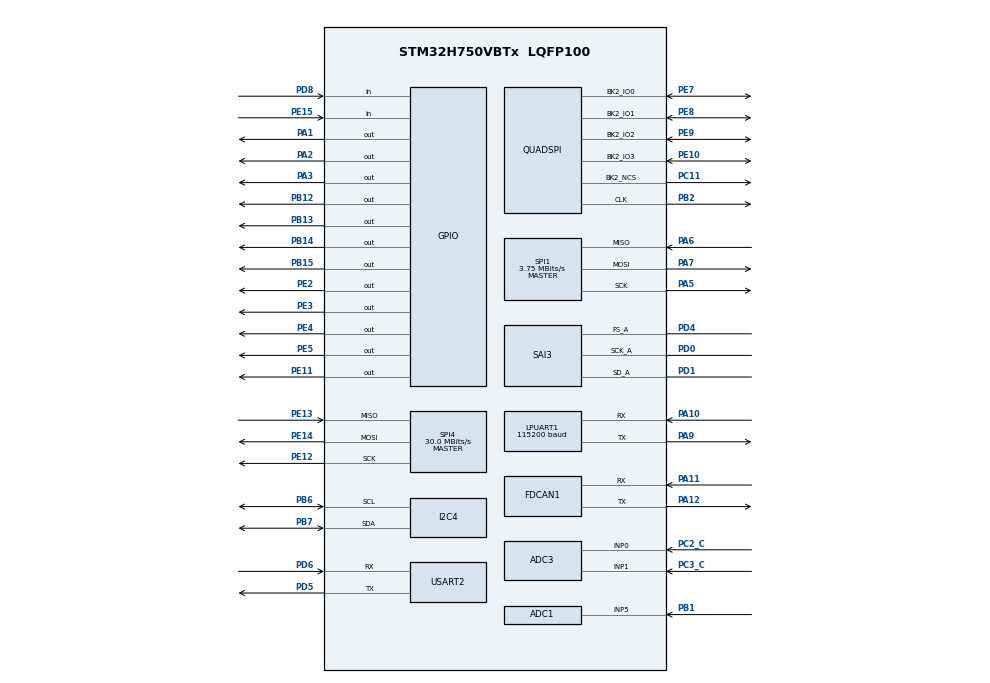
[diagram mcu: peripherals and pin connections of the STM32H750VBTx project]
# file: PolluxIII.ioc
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ADC1.Channel-0\#ChannelRegularConversion=ADC_CHANNEL_5
ADC1.ClockPrescaler=ADC_CLOCK_ASYNC_DIV2
ADC1.NbrOfConversionFlag=1
ADC1.OffsetNumber-0\#ChannelRegularConversion=ADC_OFFSET_NONE
ADC1.OffsetSignedSaturation-0\#ChannelRegularConversion=DISABLE
ADC1.Rank-0\#ChannelRegularConversion=1
ADC1.SamplingTime-0\#ChannelRegularConversion=ADC_SAMPLETIME_1CYCLE_5
ADC1.master=1
ADC2.Channel-0\#ChannelRegularConversion=ADC_CHANNEL_5
ADC2.ClockPrescaler=ADC_CLOCK_ASYNC_DIV2
ADC2.NbrOfConversionFlag=1
ADC2.OffsetNumber-0\#ChannelRegularConversion=ADC_OFFSET_NONE
ADC2.OffsetSignedSaturation-0\#ChannelRegularConversion=DISABLE
ADC2.Rank-0\#ChannelRegularConversion=1
ADC2.SamplingTime-0\#ChannelRegularConversion=ADC_SAMPLETIME_1CYCLE_5
ADC3.Channel-0\#ChannelRegularConversion=ADC_CHANNEL_0
ADC3.ClockPrescaler=ADC_CLOCK_ASYNC_DIV2
ADC3.NbrOfConversionFlag=1
ADC3.OffsetNumber-0\#ChannelRegularConversion=ADC_OFFSET_NONE
ADC3.OffsetSignedSaturation-0\#ChannelRegularConversion=DISABLE
ADC3.Rank-0\#ChannelRegularConversion=1
ADC3.SamplingTime-0\#ChannelRegularConversion=ADC_SAMPLETIME_1CYCLE_5
Bdma.LPUART1_RX.0.Direction=DMA_PERIPH_TO_MEMORY
Bdma.LPUART1_RX.0.EventEnable=DISABLE
Bdma.LPUART1_RX.0.Instance=BDMA_Channel0
Bdma.LPUART1_RX.0.MemDataAlignment=DMA_MDATAALIGN_BYTE
Bdma.LPUART1_RX.0.MemInc=DMA_MINC_ENABLE
Bdma.LPUART1_RX.0.Mode=DMA_NORMAL
Bdma.LPUART1_RX.0.PeriphDataAlignment=DMA_PDATAALIGN_BYTE
Bdma.LPUART1_RX.0.PeriphInc=DMA_PINC_DISABLE
Bdma.LPUART1_RX.0.Polarity=HAL_DMAMUX_REQ_GEN_RISING
Bdma.LPUART1_RX.0.Priority=DMA_PRIORITY_LOW
Bdma.LPUART1_RX.0.RequestNumber=1
Bdma.LPUART1_RX.0.SignalID=NONE
Bdma.LPUART1_RX.0.SyncEnable=DISABLE
Bdma.LPUART1_RX.0.SyncPolarity=HAL_DMAMUX_SYNC_NO_EVENT
Bdma.LPUART1_RX.0.SyncRequestNumber=1
Bdma.LPUART1_RX.0.SyncSignalID=NONE
Bdma.LPUART1_TX.1.Direction=DMA_MEMORY_TO_PERIPH
Bdma.LPUART1_TX.1.EventEnable=DISABLE
Bdma.LPUART1_TX.1.Instance=BDMA_Channel1
Bdma.LPUART1_TX.1.MemDataAlignment=DMA_MDATAALIGN_BYTE
Bdma.LPUART1_TX.1.MemInc=DMA_MINC_ENABLE
Bdma.LPUART1_TX.1.Mode=DMA_NORMAL
Bdma.LPUART1_TX.1.PeriphDataAlignment=DMA_PDATAALIGN_BYTE
Bdma.LPUART1_TX.1.PeriphInc=DMA_PINC_DISABLE
Bdma.LPUART1_TX.1.Polarity=HAL_DMAMUX_REQ_GEN_RISING
Bdma.LPUART1_TX.1.Priority=DMA_PRIORITY_LOW
Bdma.LPUART1_TX.1.RequestNumber=1
Bdma.LPUART1_TX.1.SignalID=NONE
Bdma.LPUART1_TX.1.SyncEnable=DISABLE
Bdma.LPUART1_TX.1.SyncPolarity=HAL_DMAMUX_SYNC_NO_EVENT
Bdma.LPUART1_TX.1.SyncRequestNumber=1
Bdma.LPUART1_TX.1.SyncSignalID=NONE
Bdma.Request0=LPUART1_RX
Bdma.Request1=LPUART1_TX
Bdma.RequestsNb=2
Dma.Request0=USART2_RX
Dma.Request1=SPI4_RX
Dma.Request2=SPI4_TX
Dma.SPI4_RX.1.Direction=DMA_PERIPH_TO_MEMORY
Dma.SPI4_RX.1.EventEnable=DISABLE
Dma.SPI4_RX.1.FIFOMode=DMA_FIFOMODE_ENABLE
Dma.SPI4_RX.1.FIFOThreshold=DMA_FIFO_THRESHOLD_3QUARTERSFULL
Dma.SPI4_RX.1.Instance=DMA1_Stream1
Dma.SPI4_RX.1.MemBurst=DMA_MBURST_SINGLE
Dma.SPI4_RX.1.MemDataAlignment=DMA_MDATAALIGN_BYTE
Dma.SPI4_RX.1.MemInc=DMA_MINC_ENABLE
Dma.SPI4_RX.1.Mode=DMA_NORMAL
Dma.SPI4_RX.1.PeriphBurst=DMA_PBURST_SINGLE
Dma.SPI4_RX.1.PeriphDataAlignment=DMA_PDATAALIGN_BYTE
Dma.SPI4_RX.1.PeriphInc=DMA_PINC_DISABLE
Dma.SPI4_RX.1.Polarity=HAL_DMAMUX_REQ_GEN_RISING
Dma.SPI4_RX.1.Priority=DMA_PRIORITY_LOW
Dma.SPI4_RX.1.RequestNumber=1
Dma.SPI4_RX.1.SignalID=NONE
Dma.SPI4_RX.1.SyncEnable=DISABLE
Dma.SPI4_RX.1.SyncPolarity=HAL_DMAMUX_SYNC_NO_EVENT
Dma.SPI4_RX.1.SyncRequestNumber=1
Dma.SPI4_RX.1.SyncSignalID=NONE
Dma.SPI4_TX.2.Direction=DMA_MEMORY_TO_PERIPH
Dma.SPI4_TX.2.EventEnable=DISABLE
Dma.SPI4_TX.2.FIFOMode=DMA_FIFOMODE_ENABLE
Dma.SPI4_TX.2.FIFOThreshold=DMA_FIFO_THRESHOLD_3QUARTERSFULL
Dma.SPI4_TX.2.Instance=DMA1_Stream2
Dma.SPI4_TX.2.MemBurst=DMA_MBURST_SINGLE
Dma.SPI4_TX.2.MemDataAlignment=DMA_MDATAALIGN_BYTE
Dma.SPI4_TX.2.MemInc=DMA_MINC_ENABLE
Dma.SPI4_TX.2.Mode=DMA_NORMAL
Dma.SPI4_TX.2.PeriphBurst=DMA_PBURST_SINGLE
Dma.SPI4_TX.2.PeriphDataAlignment=DMA_PDATAALIGN_BYTE
Dma.SPI4_TX.2.PeriphInc=DMA_PINC_DISABLE
Dma.SPI4_TX.2.Polarity=HAL_DMAMUX_REQ_GEN_RISING
Dma.SPI4_TX.2.Priority=DMA_PRIORITY_LOW
Dma.SPI4_TX.2.RequestNumber=1
Dma.SPI4_TX.2.SignalID=NONE
Dma.SPI4_TX.2.SyncEnable=DISABLE
Dma.SPI4_TX.2.SyncPolarity=HAL_DMAMUX_SYNC_NO_EVENT
Dma.SPI4_TX.2.SyncRequestNumber=1
Dma.SPI4_TX.2.SyncSignalID=NONE
Dma.USART2_RX.0.Direction=DMA_PERIPH_TO_MEMORY
Dma.USART2_RX.0.EventEnable=DISABLE
Dma.USART2_RX.0.FIFOMode=DMA_FIFOMODE_ENABLE
Dma.USART2_RX.0.FIFOThreshold=DMA_FIFO_THRESHOLD_FULL
Dma.USART2_RX.0.Instance=DMA1_Stream0
Dma.USART2_RX.0.MemBurst=DMA_MBURST_SINGLE
Dma.USART2_RX.0.MemDataAlignment=DMA_MDATAALIGN_BYTE
Dma.USART2_RX.0.MemInc=DMA_MINC_ENABLE
Dma.USART2_RX.0.Mode=DMA_CIRCULAR
Dma.USART2_RX.0.PeriphBurst=DMA_PBURST_SINGLE
Dma.USART2_RX.0.PeriphDataAlignment=DMA_PDATAALIGN_BYTE
Dma.USART2_RX.0.PeriphInc=DMA_PINC_DISABLE
Dma.USART2_RX.0.Polarity=HAL_DMAMUX_REQ_GEN_RISING
Dma.USART2_RX.0.Priority=DMA_PRIORITY_VERY_HIGH
Dma.USART2_RX.0.RequestNumber=1
Dma.USART2_RX.0.SignalID=NONE
Dma.USART2_RX.0.SyncEnable=DISABLE
Dma.USART2_RX.0.SyncPolarity=HAL_DMAMUX_SYNC_NO_EVENT
Dma.USART2_RX.0.SyncRequestNumber=1
Dma.USART2_RX.0.SyncSignalID=NONE
FREERTOS.Tasks01=systemd,0,1024,systemd_main,Default,NULL,Dynamic,NULL,NULL
FREERTOS.configCHECK_FOR_STACK_OVERFLOW=1
FREERTOS.configTOTAL_HEAP_SIZE=262144
FREERTOS.configUSE_COUNTING_SEMAPHORES=1
FREERTOS.configUSE_NEWLIB_REENTRANT=1
I2C4.Speed=100
I2C4.Timing=0x307075B1
JPEG.JPEG_RGB_FORMAT=JPEG_RGB565
LPUART1.BaudRate=115200
LPUART1.FIFOMode=UART_FIFOMODE_ENABLE
LPUART1.OverrunDisableParam=UART_ADVFEATURE_OVERRUN_DISABLE
LPUART1.RXFIFOThreshold=UART_RXFIFO_THRESHOLD_1_2
LPUART1.TXFIFOThreshold=UART_TXFIFO_THRESHOLD_1_2
Mcu.Family=STM32H7
Mcu.Name=STM32H750VBTx
Mcu.Package=LQFP100
Mdma.MDMA_Channel0.JPEG_INFIFO_TH.0.BlockCount=0
Mdma.MDMA_Channel0.JPEG_INFIFO_TH.0.BlockDataLength=0
Mdma.MDMA_Channel0.JPEG_INFIFO_TH.0.BufferTransferLength=32
Mdma.MDMA_Channel0.JPEG_INFIFO_TH.0.CircularMode=MDMA_LINEAR_LIST
Mdma.MDMA_Channel0.JPEG_INFIFO_TH.0.DataAlignment=MDMA_DATAALIGN_PACKENABLE
Mdma.MDMA_Channel0.JPEG_INFIFO_TH.0.DestBlockAddressOffset=0
Mdma.MDMA_Channel0.JPEG_INFIFO_TH.0.DestBurst=MDMA_DEST_BURST_SINGLE
Mdma.MDMA_Channel0.JPEG_INFIFO_TH.0.DestDataSize=MDMA_DEST_DATASIZE_WORD
Mdma.MDMA_Channel0.JPEG_INFIFO_TH.0.DestinationInc=MDMA_DEST_INC_DISABLE
Mdma.MDMA_Channel0.JPEG_INFIFO_TH.0.DstAddress=0
Mdma.MDMA_Channel0.JPEG_INFIFO_TH.0.Endianness=MDMA_LITTLE_ENDIANNESS_PRESERVE
Mdma.MDMA_Channel0.JPEG_INFIFO_TH.0.Instance=MDMA_Channel0
Mdma.MDMA_Channel0.JPEG_INFIFO_TH.0.MaskAddress=0
Mdma.MDMA_Channel0.JPEG_INFIFO_TH.0.MaskData=0
Mdma.MDMA_Channel0.JPEG_INFIFO_TH.0.Priority=MDMA_PRIORITY_LOW
Mdma.MDMA_Channel0.JPEG_INFIFO_TH.0.Rank=First
Mdma.MDMA_Channel0.JPEG_INFIFO_TH.0.SourceBlockAddressOffset=0
Mdma.MDMA_Channel0.JPEG_INFIFO_TH.0.SourceBurst=MDMA_SOURCE_BURST_SINGLE
Mdma.MDMA_Channel0.JPEG_INFIFO_TH.0.SourceDataSize=MDMA_SRC_DATASIZE_BYTE
Mdma.MDMA_Channel0.JPEG_INFIFO_TH.0.SourceInc=MDMA_SRC_INC_BYTE
Mdma.MDMA_Channel0.JPEG_INFIFO_TH.0.SrcAddress=0
Mdma.MDMA_Channel0.JPEG_INFIFO_TH.0.TransferTriggerMode=MDMA_BUFFER_TRANSFER
Mdma.MDMA_Channel0.Request0=JPEG_INFIFO_TH
Mdma.MDMA_Channel0.RequestsNb=1
Mdma.MDMA_Channel1.JPEG_OUTFIFO_TH.0.BlockCount=0
Mdma.MDMA_Channel1.JPEG_OUTFIFO_TH.0.BlockDataLength=0
Mdma.MDMA_Channel1.JPEG_OUTFIFO_TH.0.BufferTransferLength=32
Mdma.MDMA_Channel1.JPEG_OUTFIFO_TH.0.CircularMode=MDMA_LINEAR_LIST
Mdma.MDMA_Channel1.JPEG_OUTFIFO_TH.0.DataAlignment=MDMA_DATAALIGN_PACKENABLE
Mdma.MDMA_Channel1.JPEG_OUTFIFO_TH.0.DestBlockAddressOffset=0
Mdma.MDMA_Channel1.JPEG_OUTFIFO_TH.0.DestBurst=MDMA_DEST_BURST_SINGLE
Mdma.MDMA_Channel1.JPEG_OUTFIFO_TH.0.DestDataSize=MDMA_DEST_DATASIZE_BYTE
Mdma.MDMA_Channel1.JPEG_OUTFIFO_TH.0.DestinationInc=MDMA_DEST_INC_BYTE
Mdma.MDMA_Channel1.JPEG_OUTFIFO_TH.0.DstAddress=0
Mdma.MDMA_Channel1.JPEG_OUTFIFO_TH.0.Endianness=MDMA_LITTLE_ENDIANNESS_PRESERVE
Mdma.MDMA_Channel1.JPEG_OUTFIFO_TH.0.Instance=MDMA_Channel1
Mdma.MDMA_Channel1.JPEG_OUTFIFO_TH.0.MaskAddress=0
Mdma.MDMA_Channel1.JPEG_OUTFIFO_TH.0.MaskData=0
Mdma.MDMA_Channel1.JPEG_OUTFIFO_TH.0.Priority=MDMA_PRIORITY_LOW
Mdma.MDMA_Channel1.JPEG_OUTFIFO_TH.0.Rank=First
Mdma.MDMA_Channel1.JPEG_OUTFIFO_TH.0.SourceBlockAddressOffset=0
Mdma.MDMA_Channel1.JPEG_OUTFIFO_TH.0.SourceBurst=MDMA_SOURCE_BURST_SINGLE
Mdma.MDMA_Channel1.JPEG_OUTFIFO_TH.0.SourceDataSize=MDMA_SRC_DATASIZE_WORD
Mdma.MDMA_Channel1.JPEG_OUTFIFO_TH.0.SourceInc=MDMA_SRC_INC_DISABLE
Mdma.MDMA_Channel1.JPEG_OUTFIFO_TH.0.SrcAddress=0
Mdma.MDMA_Channel1.JPEG_OUTFIFO_TH.0.TransferTriggerMode=MDMA_BUFFER_TRANSFER
Mdma.MDMA_Channel1.Request0=JPEG_OUTFIFO_TH
Mdma.MDMA_Channel1.RequestsNb=1
Mdma.RequestSet0=MDMA_Channel0
Mdma.RequestSet1=MDMA_Channel1
Mdma.RequestSetsNb=2
NVIC.BDMA_Channel0_IRQn=true\:5\:0\:false\:false\:true\:true\:false\:true
NVIC.BDMA_Channel1_IRQn=true\:5\:0\:false\:false\:true\:true\:false\:true
NVIC.DMA1_Stream0_IRQn=true\:5\:0\:false\:false\:true\:true\:false\:true
NVIC.DMA1_Stream1_IRQn=true\:5\:0\:false\:false\:true\:false\:true\:true
NVIC.DMA1_Stream2_IRQn=true\:5\:0\:false\:false\:true\:false\:true\:true
NVIC.MDMA_IRQn=true\:5\:0\:false\:false\:true\:true\:false\:true
NVIC.PriorityGroup=NVIC_PRIORITYGROUP_4
NVIC.SPI4_IRQn=true\:5\:0\:false\:false\:true\:false\:true\:true
NVIC.TIM1_UP_IRQn=true\:15\:0\:false\:false\:true\:false\:false\:true
NVIC.TimeBase=TIM1_UP_IRQn
NVIC.TimeBaseIP=TIM1
NVIC.USART2_IRQn=true\:5\:0\:false\:false\:true\:true\:true\:true
PA1.Signal=GPIO_Output
PA10.Mode=Asynchronous
PA10.Signal=LPUART1_RX
PA11.Mode=FDCAN_Activate
PA11.Signal=FDCAN1_RX
PA12.Mode=FDCAN_Activate
PA12.Signal=FDCAN1_TX
PA13\ (JTMS/SWDIO).Mode=JTAG_5_pins
PA13\ (JTMS/SWDIO).Signal=DEBUG_JTMS-SWDIO
PA14\ (JTCK/SWCLK).Mode=JTAG_5_pins
PA14\ (JTCK/SWCLK).Signal=DEBUG_JTCK-SWCLK
PA15\ (JTDI).Mode=JTAG_5_pins
PA15\ (JTDI).Signal=DEBUG_JTDI
PA2.Signal=GPIO_Output
PA3.Signal=GPIO_Output
PA5.Mode=Full_Duplex_Master
PA5.Signal=SPI1_SCK
PA6.Mode=Full_Duplex_Master
PA6.Signal=SPI1_MISO
PA7.Mode=Full_Duplex_Master
PA7.Signal=SPI1_MOSI
PA9.Mode=Asynchronous
PA9.Signal=LPUART1_TX
PB1.Signal=ADCx_INP5
PB12.PinState=GPIO_PIN_SET
PB12.Signal=GPIO_Output
PB13.PinState=GPIO_PIN_SET
PB13.Signal=GPIO_Output
PB14.Signal=GPIO_Output
PB15.Signal=GPIO_Output
PB2.GPIO_Speed=GPIO_SPEED_FREQ_VERY_HIGH
PB2.Mode=Single Bank 2
PB2.Signal=QUADSPI_CLK
PB3\ (JTDO/TRACESWO).Mode=JTAG_5_pins
PB3\ (JTDO/TRACESWO).Signal=DEBUG_JTDO-SWO
PB4\ (NJTRST).Mode=JTAG_5_pins
PB4\ (NJTRST).Signal=DEBUG_JTRST
PB6.GPIO_Pu=GPIO_PULLUP
PB6.Mode=I2C
PB6.Signal=I2C4_SCL
PB7.GPIO_Pu=GPIO_PULLUP
PB7.Mode=I2C
PB7.Signal=I2C4_SDA
PC11.GPIO_Speed=GPIO_SPEED_FREQ_VERY_HIGH
PC11.Mode=Single Bank 2
PC11.Signal=QUADSPI_BK2_NCS
PC2_C.Mode=IN0-Single-Ended
PC2_C.Signal=ADC3_INP0
PC3_C.Mode=IN1-Single-Ended
PC3_C.Signal=ADC3_INP1
PD0.Mode=SAI_A_Master
PD0.Signal=SAI3_SCK_A
PD1.Mode=SAI_A_Master
PD1.Signal=SAI3_SD_A
PD4.Mode=SAI_A_Master
PD4.Signal=SAI3_FS_A
PD5.Mode=Asynchronous
PD5.Signal=USART2_TX
PD6.Mode=Asynchronous
PD6.Signal=USART2_RX
PD8.Signal=GPIO_Input
PE10.GPIO_Speed=GPIO_SPEED_FREQ_VERY_HIGH
PE10.Mode=Single Bank 2
PE10.Signal=QUADSPI_BK2_IO3
PE11.Signal=GPIO_Output
PE12.Mode=Full_Duplex_Master
PE12.Signal=SPI4_SCK
PE13.Mode=Full_Duplex_Master
PE13.Signal=SPI4_MISO
PE14.Mode=Full_Duplex_Master
PE14.Signal=SPI4_MOSI
PE15.Signal=GPIO_Input
PE2.PinState=GPIO_PIN_SET
PE2.Signal=GPIO_Output
PE3.PinState=GPIO_PIN_SET
PE3.Signal=GPIO_Output
PE4.Signal=GPIO_Output
PE5.Signal=GPIO_Output
PE7.GPIO_Speed=GPIO_SPEED_FREQ_VERY_HIGH
PE7.Mode=Single Bank 2
PE7.Signal=QUADSPI_BK2_IO0
PE8.GPIO_Speed=GPIO_SPEED_FREQ_VERY_HIGH
PE8.Mode=Single Bank 2
PE8.Signal=QUADSPI_BK2_IO1
PE9.GPIO_Speed=GPIO_SPEED_FREQ_VERY_HIGH
PE9.Mode=Single Bank 2
PE9.Signal=QUADSPI_BK2_IO2
PH0-OSC_IN\ (PH0).Mode=HSE-External-Oscillator
PH0-OSC_IN\ (PH0).Signal=RCC_OSC_IN
PH1-OSC_OUT\ (PH1).Mode=HSE-External-Oscillator
PH1-OSC_OUT\ (PH1).Signal=RCC_OSC_OUT
ProjectManager.HeapSize=0x200
ProjectManager.StackSize=0x400
ProjectManager.TargetToolchain=STM32CubeIDE
QUADSPI.ClockMode=QSPI_CLOCK_MODE_3
QUADSPI.FlashSize=29
QUADSPI.SampleShifting=QSPI_SAMPLE_SHIFTING_HALFCYCLE
RCC.ADCCLockSelection=RCC_ADCCLKSOURCE_PLL3
RCC.ADCFreq_Value=150000000
RCC.APB1Freq_Value=120000000
RCC.APB2Freq_Value=120000000
RCC.APB3Freq_Value=120000000
RCC.APB4Freq_Value=120000000
RCC.CortexFreq_Value=480000000
RCC.D1PPRE=RCC_APB3_DIV2
RCC.D2PPRE1=RCC_APB1_DIV2
RCC.D2PPRE2=RCC_APB2_DIV2
RCC.D3PPRE=RCC_APB4_DIV2
RCC.DIVM1=2
RCC.DIVM2=2
RCC.DIVM3=16
RCC.DIVN1=64
RCC.DIVN2=16
RCC.DIVN3=160
RCC.FDCANCLockSelection=RCC_FDCANCLKSOURCE_PLL2
RCC.HCLKFreq_Value=240000000
RCC.HPRE=RCC_HCLK_DIV2
RCC.HSE_VALUE=30000000
RCC.HSIDiv=RCC_PLLSAIDIVR_8
RCC.PLL1_VCI_Range-AdvancedSettings=RCC_PLL1VCIRANGE_0
RCC.PLL1_VCO_SEL-AdvancedSettings=RCC_PLL1VCOMEDIUM
RCC.PLL2FRACN=0
RCC.PLL2_VCI_Range-AdvancedSettings=RCC_PLL2VCIRANGE_0
RCC.PLL3FRACN=0
RCC.PLLFRACN=0
RCC.PLLSourceVirtual=RCC_PLLSOURCE_HSE
RCC.SAI23CLockSelection=RCC_SAI23CLKSOURCE_PLL3
RCC.SPI123CLockSelection=RCC_SPI123CLKSOURCE_PLL2
RCC.SYSCLKFreq_VALUE=480000000
RCC.SYSCLKSource=RCC_SYSCLKSOURCE_PLLCLK
RCC.USBFreq_Value=480000000
SAI3.ErrorAudioFreq-SAI_A_Master=52.58 %
SAI3.Instance-SAI_A_Master=SAI$Index_Block_A
SAI3.MClockEnable-SAI_A_Master=SAI_MASTERCLOCK_DISABLE
SAI3.RealAudioFreq-SAI_A_Master=292.968 KHz
SAI3.VirtualMode-SAI_A_Master=VM_MASTER
SH.ADCx_INP5.0=ADC1_INP5,IN5-Single-Ended
SH.ADCx_INP5.1=ADC2_INP5,IN5-Single-Ended
SPI1.BaudRatePrescaler=SPI_BAUDRATEPRESCALER_32
SPI1.CLKPolarity=SPI_POLARITY_HIGH
SPI1.CalculateBaudRate=3.75 MBits/s
SPI1.DataSize=SPI_DATASIZE_8BIT
SPI1.Direction=SPI_DIRECTION_2LINES
SPI1.Mode=SPI_MODE_MASTER
SPI1.VirtualType=VM_MASTER
SPI4.BaudRatePrescaler=SPI_BAUDRATEPRESCALER_4
SPI4.CalculateBaudRate=30.0 MBits/s
SPI4.DataSize=SPI_DATASIZE_8BIT
SPI4.Direction=SPI_DIRECTION_2LINES
SPI4.Mode=SPI_MODE_MASTER
SPI4.VirtualType=VM_MASTER
TIM2.AutoReloadPreload=TIM_AUTORELOAD_PRELOAD_ENABLE
TIM2.Prescaler=240
USART2.VirtualMode-Asynchronous=VM_ASYNC
VP_FREERTOS_VS_CMSIS_V1.Mode=CMSIS_V1
VP_IWDG1_VS_IWDG.Mode=IWDG_Activate
VP_JPEG_VS_JPEG.Mode=JPEG_Activate
VP_SYS_VS_tim1.Mode=TIM1
VP_TIM2_VS_ClockSourceITR.Mode=TriggerSource_ITR0
board=custom

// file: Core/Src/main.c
/* USER CODE BEGIN Header */
/**
  ******************************************************************************
  * @file           : main.c
  * @brief          : Main program body
  ******************************************************************************
  * @attention
  *
  * <h2><center>&copy; Copyright (c) 2021 STMicroelectronics.
  * All rights reserved.</center></h2>
  *
  * This software component is licensed by ST under BSD 3-Clause license,
  * the "License"; You may not use this file except in compliance with the
  * License. You may obtain a copy of the License at:
  *                        opensource.org/licenses/BSD-3-Clause
  *
  ******************************************************************************
  */
/* USER CODE END Header */
#include "main.h"
#include "cmsis_os.h"
#include "adc.h"
#include "bdma.h"
#include "fdcan.h"
#include "i2c.h"
#include "iwdg.h"
#include "jpeg.h"
#include "usart.h"
#include "mdma.h"
#include "quadspi.h"
#include "sai.h"
#include "tim.h"
#include "gpio.h"

void SystemClock_Config(void);
void PeriphCommonClock_Config(void);
void MX_FREERTOS_Init(void);

int main(void)
{

  /* MCU Configuration--------------------------------------------------------*/

  /* Reset of all peripherals, Initializes the Flash interface and the Systick. */
  HAL_Init();

  /* Configure the system clock */
  SystemClock_Config();

/* Configure the peripherals common clocks */
  PeriphCommonClock_Config();

  /* USER CODE BEGIN SysInit */

  /* WARRRRNNNNNNNN */
  /* WARRRRNNNNNNNN */
  /* WARRRRNNNNNNNN */
  /* WARRRRNNNNNNNN */
  /* WARRRRNNNNNNNN */
  /* WARRRRNNNNNNNN */

  /* PUT THE FKIN MX_DMA_Init BEFORE THE FKIN MX_USART1_UART_Init !!!!!!!!! */

  /* WARRRRNNNNNNNN */
  /* WARRRRNNNNNNNN */
  /* WARRRRNNNNNNNN */
  /* WARRRRNNNNNNNN */
  /* WARRRRNNNNNNNN */
  /* WARRRRNNNNNNNN */

  /* USER CODE END SysInit */

  /* Initialize all configured peripherals */
  MX_GPIO_Init();
  MX_ADC1_Init();
  MX_ADC2_Init();
  MX_ADC3_Init();
  MX_I2C4_Init();
  MX_LPUART1_UART_Init();
  MX_BDMA_Init();
  MX_SAI3_Init();
  MX_DMA_Init();
  MX_MDMA_Init();
  MX_FDCAN1_Init();
  MX_SPI4_Init();
  MX_USART2_UART_Init();
  MX_SPI1_Init();
  MX_JPEG_Init();
  //MX_IWDG1_Init();
  MX_QUADSPI_Init();
  MX_TIM2_Init();

  /* Call init function for freertos objects (in freertos.c) */
  MX_FREERTOS_Init();
  /* Start scheduler */
  osKernelStart();

  /* We should never get here as control is now taken by the scheduler */
  /* Infinite loop */
  while (1)
  {

  }
}

void SystemClock_Config(void)
{
  RCC_OscInitTypeDef RCC_OscInitStruct = {0};
  RCC_ClkInitTypeDef RCC_ClkInitStruct = {0};

  /** Supply configuration update enable
  */
  HAL_PWREx_ConfigSupply(PWR_LDO_SUPPLY);
  /** Configure the main internal regulator output voltage
  */
  __HAL_PWR_VOLTAGESCALING_CONFIG(PWR_REGULATOR_VOLTAGE_SCALE0);

  while(!__HAL_PWR_GET_FLAG(PWR_FLAG_VOSRDY)) {}
  /** Macro to configure the PLL clock source
  */
  __HAL_RCC_PLL_PLLSOURCE_CONFIG(RCC_PLLSOURCE_HSE);
  /** Initializes the RCC Oscillators according to the specified parameters
  * in the RCC_OscInitTypeDef structure.
  */
  RCC_OscInitStruct.OscillatorType = RCC_OSCILLATORTYPE_LSI|RCC_OSCILLATORTYPE_HSE;
  RCC_OscInitStruct.HSEState = RCC_HSE_ON;
  RCC_OscInitStruct.LSIState = RCC_LSI_ON;
  RCC_OscInitStruct.PLL.PLLState = RCC_PLL_ON;
  RCC_OscInitStruct.PLL.PLLSource = RCC_PLLSOURCE_HSE;
  RCC_OscInitStruct.PLL.PLLM = 2;
  RCC_OscInitStruct.PLL.PLLN = 64;
  RCC_OscInitStruct.PLL.PLLP = 2;
  RCC_OscInitStruct.PLL.PLLQ = 2;
  RCC_OscInitStruct.PLL.PLLR = 2;
  RCC_OscInitStruct.PLL.PLLRGE = RCC_PLL1VCIRANGE_3;
  RCC_OscInitStruct.PLL.PLLVCOSEL = RCC_PLL1VCOWIDE;
  RCC_OscInitStruct.PLL.PLLFRACN = 0;
  if (HAL_RCC_OscConfig(&RCC_OscInitStruct) != HAL_OK)
  {
    Error_Handler();
  }
  /** Initializes the CPU, AHB and APB buses clocks
  */
  RCC_ClkInitStruct.ClockType = RCC_CLOCKTYPE_HCLK|RCC_CLOCKTYPE_SYSCLK
                              |RCC_CLOCKTYPE_PCLK1|RCC_CLOCKTYPE_PCLK2
                              |RCC_CLOCKTYPE_D3PCLK1|RCC_CLOCKTYPE_D1PCLK1;
  RCC_ClkInitStruct.SYSCLKSource = RCC_SYSCLKSOURCE_PLLCLK;
  RCC_ClkInitStruct.SYSCLKDivider = RCC_SYSCLK_DIV1;
  RCC_ClkInitStruct.AHBCLKDivider = RCC_HCLK_DIV2;
  RCC_ClkInitStruct.APB3CLKDivider = RCC_APB3_DIV2;
  RCC_ClkInitStruct.APB1CLKDivider = RCC_APB1_DIV2;
  RCC_ClkInitStruct.APB2CLKDivider = RCC_APB2_DIV2;
  RCC_ClkInitStruct.APB4CLKDivider = RCC_APB4_DIV2;

  if (HAL_RCC_ClockConfig(&RCC_ClkInitStruct, FLASH_LATENCY_4) != HAL_OK)
  {
    Error_Handler();
  }
}

void PeriphCommonClock_Config(void)
{
  RCC_PeriphCLKInitTypeDef PeriphClkInitStruct = {0};

  /** Initializes the peripherals clock
  */
  PeriphClkInitStruct.PeriphClockSelection = RCC_PERIPHCLK_ADC|RCC_PERIPHCLK_SAI3
                              |RCC_PERIPHCLK_SPI1|RCC_PERIPHCLK_FDCAN;
  PeriphClkInitStruct.PLL2.PLL2M = 2;
  PeriphClkInitStruct.PLL2.PLL2N = 16;
  PeriphClkInitStruct.PLL2.PLL2P = 2;
  PeriphClkInitStruct.PLL2.PLL2Q = 2;
  PeriphClkInitStruct.PLL2.PLL2R = 2;
  PeriphClkInitStruct.PLL2.PLL2RGE = RCC_PLL2VCIRANGE_3;
  PeriphClkInitStruct.PLL2.PLL2VCOSEL = RCC_PLL2VCOWIDE;
  PeriphClkInitStruct.PLL2.PLL2FRACN = 0;
  PeriphClkInitStruct.PLL3.PLL3M = 16;
  PeriphClkInitStruct.PLL3.PLL3N = 160;
  PeriphClkInitStruct.PLL3.PLL3P = 2;
  PeriphClkInitStruct.PLL3.PLL3Q = 2;
  PeriphClkInitStruct.PLL3.PLL3R = 2;
  PeriphClkInitStruct.PLL3.PLL3RGE = RCC_PLL3VCIRANGE_0;
  PeriphClkInitStruct.PLL3.PLL3VCOSEL = RCC_PLL3VCOWIDE;
  PeriphClkInitStruct.PLL3.PLL3FRACN = 0;
  PeriphClkInitStruct.Sai23ClockSelection = RCC_SAI23CLKSOURCE_PLL3;
  PeriphClkInitStruct.Spi123ClockSelection = RCC_SPI123CLKSOURCE_PLL2;
  PeriphClkInitStruct.FdcanClockSelection = RCC_FDCANCLKSOURCE_PLL2;
  PeriphClkInitStruct.AdcClockSelection = RCC_ADCCLKSOURCE_PLL3;
  if (HAL_RCCEx_PeriphCLKConfig(&PeriphClkInitStruct) != HAL_OK)
  {
    Error_Handler();
  }
}

void HAL_TIM_PeriodElapsedCallback(TIM_HandleTypeDef *htim)
{
  if (htim->Instance == TIM1) {
    HAL_IncTick();
  }
}

void Error_Handler(void)
{
  __disable_irq();
  while (1)
  {
  }
}

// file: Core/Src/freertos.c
/* USER CODE BEGIN Header */
/**
  ******************************************************************************
  * File Name          : freertos.c
  * Description        : Code for freertos applications
  ******************************************************************************
  * @attention
  *
  * Copyright (c) 2022 STMicroelectronics.
  * All rights reserved.
  *
  * This software is licensed under terms that can be found in the LICENSE file
  * in the root directory of this software component.
  * If no LICENSE file comes with this software, it is provided AS-IS.
  *
  ******************************************************************************
  */
/* USER CODE END Header */

#include "FreeRTOS.h"
#include "task.h"
#include "main.h"
#include "cmsis_os.h"

/* USER CODE BEGIN Includes */
#include "System.h"
/* USER CODE END Includes */

osThreadId systemdHandle;

void systemd_main(void const * argument);

void MX_FREERTOS_Init(void); /* (MISRA C 2004 rule 8.1) */

/* GetIdleTaskMemory prototype (linked to static allocation support) */
void vApplicationGetIdleTaskMemory( StaticTask_t **ppxIdleTaskTCBBuffer, StackType_t **ppxIdleTaskStackBuffer, uint32_t *pulIdleTaskStackSize );

/* Hook prototypes */
void vApplicationStackOverflowHook(xTaskHandle xTask, signed char *pcTaskName);

/* USER CODE BEGIN 4 */
__weak void vApplicationStackOverflowHook(xTaskHandle xTask, signed char *pcTaskName)
{
   /* Run time stack overflow checking is performed if
   configCHECK_FOR_STACK_OVERFLOW is defined to 1 or 2. This hook function is
   called if a stack overflow is detected. */
}
/* USER CODE END 4 */

/* USER CODE BEGIN GET_IDLE_TASK_MEMORY */
static StaticTask_t xIdleTaskTCBBuffer;
static StackType_t xIdleStack[configMINIMAL_STACK_SIZE];

void vApplicationGetIdleTaskMemory( StaticTask_t **ppxIdleTaskTCBBuffer, StackType_t **ppxIdleTaskStackBuffer, uint32_t *pulIdleTaskStackSize )
{
  *ppxIdleTaskTCBBuffer = &xIdleTaskTCBBuffer;
  *ppxIdleTaskStackBuffer = &xIdleStack[0];
  *pulIdleTaskStackSize = configMINIMAL_STACK_SIZE;
  /* place for user code */
}
/* USER CODE END GET_IDLE_TASK_MEMORY */

void MX_FREERTOS_Init(void) {

  /* Create the thread(s) */
  /* definition and creation of systemd */
  osThreadDef(systemd, systemd_main, osPriorityNormal, 0, 1024);
  systemdHandle = osThreadCreate(osThread(systemd), NULL);

}

void systemd_main(void const * argument)
{
  /* USER CODE BEGIN systemd_main */
	systemd_init();
  /* Infinite loop */
  for(;;)
  {
    osDelay(1);
  }
  /* USER CODE END systemd_main */
}
